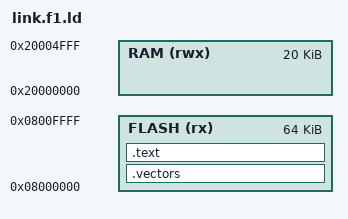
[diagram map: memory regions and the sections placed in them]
MEMORY
{
    FLASH (rx) : ORIGIN = 0x08000000, LENGTH = 64K
    RAM  (rwx): ORIGIN = 0x20000000, LENGTH = 20K
}

SECTIONS
{
    .vectors ORIGIN(FLASH) :
    {
        KEEP(*(.vectors))
    } > FLASH

    .text :
    {
        *(.text*)
        *(.rodata*)
    } > FLASH
}
